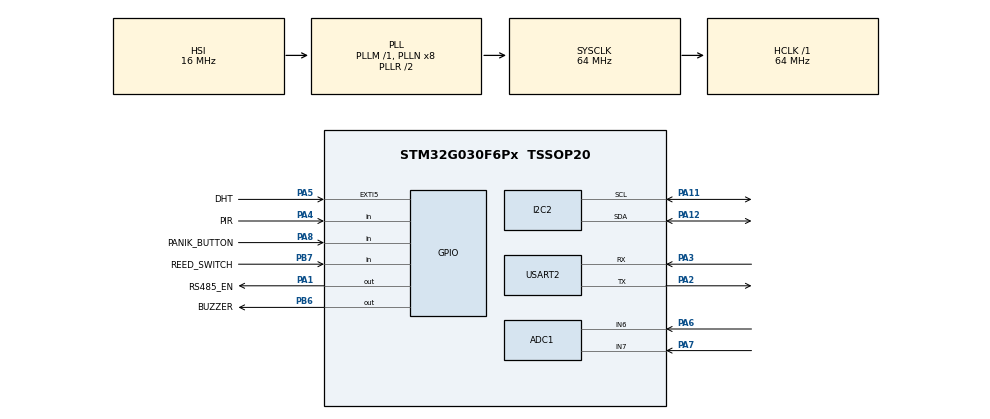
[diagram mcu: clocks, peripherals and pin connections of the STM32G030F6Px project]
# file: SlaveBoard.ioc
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ADC1.Channel-0\#ChannelRegularConversion=ADC_CHANNEL_6
ADC1.Channel-1\#ChannelRegularConversion=ADC_CHANNEL_7
ADC1.NbrOfConversion=2
ADC1.NbrOfConversionFlag=1
ADC1.Rank-0\#ChannelRegularConversion=1
ADC1.Rank-1\#ChannelRegularConversion=2
ADC1.SamplingTime-0\#ChannelRegularConversion=ADC_SAMPLINGTIME_COMMON_1
ADC1.SamplingTime-1\#ChannelRegularConversion=ADC_SAMPLINGTIME_COMMON_1
ADC1.SamplingTimeCommon1=ADC_SAMPLETIME_160CYCLES_5
ADC1.SamplingTimeCommon2=ADC_SAMPLETIME_160CYCLES_5
ADC1.SelectedChannel=ADC_CHANNEL_6|ADC_CHANNEL_7
ADC1.master=1
I2C2.Timing=0x10B17DB5
Mcu.Family=STM32G0
Mcu.Name=STM32G030F6Px
Mcu.Package=TSSOP20
NVIC.EXTI4_15_IRQn=true\:0\:0\:false\:false\:true\:true\:true\:true
NVIC.TIM3_IRQn=true\:0\:0\:false\:false\:true\:true\:true\:true
PA1.GPIO_Label=RS485_EN
PA1.Signal=GPIO_Output
PA11\ [PA9].Mode=I2C
PA11\ [PA9].Signal=I2C2_SCL
PA12\ [PA10].Mode=I2C
PA12\ [PA10].Signal=I2C2_SDA
PA13.Mode=Serial_Wire
PA13.Signal=SYS_SWDIO
PA14-BOOT0.Mode=Serial_Wire
PA14-BOOT0.Signal=SYS_SWCLK
PA14-BOOT0__PA15.StandardMode=true
PA2.Mode=Asynchronous
PA2.Signal=USART2_TX
PA3.Mode=Asynchronous
PA3.Signal=USART2_RX
PA4.GPIO_Label=PIR
PA4.Signal=GPIO_Input
PA5.GPIO_Label=DHT
PA5.Signal=GPXTI5
PA6.Mode=IN6
PA6.Signal=ADC1_IN6
PA7.Mode=IN7
PA7.Signal=ADC1_IN7
PA8.GPIO_Label=PANIK_BUTTON
PA8.Signal=GPIO_Input
PB0__PB1__PB2__PA8.StandardMode=true
PB3__PB4__PB5__PB6.StandardMode=true
PB6.GPIO_Label=BUZZER
PB6.Signal=GPIO_Output
PB7.GPIO_Label=REED_SWITCH
PB7.Signal=GPIO_Input
PB7__PB8.StandardMode=true
PC14-OSC32_IN\ (PC14)__PB9.StandardMode=true
ProjectManager.HeapSize=0x200
ProjectManager.StackSize=0x400
ProjectManager.TargetToolchain=MDK-ARM V5.32
RCC.ADCFreq_Value=64000000
RCC.AHBFreq_Value=64000000
RCC.CortexFreq_Value=64000000
RCC.EXTERNAL_CLOCK_VALUE=12288000
RCC.HCLKFreq_Value=64000000
RCC.HSE_VALUE=8000000
RCC.HSI_VALUE=16000000
RCC.LSE_VALUE=32768
RCC.SYSCLKFreq_VALUE=64000000
RCC.SYSCLKSource=RCC_SYSCLKSOURCE_PLLCLK
RCC.VCOOutputFreq_Value=128000000
TIM3.Prescaler=1000-1
USART2.VirtualMode-Asynchronous=VM_ASYNC
VP_TIM1_VS_ClockSourceINT.Mode=Internal
VP_TIM3_VS_ClockSourceINT.Mode=Internal
board=custom

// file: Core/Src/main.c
/* USER CODE BEGIN Header */
/**
  ******************************************************************************
  * @file           : main.c
  * @brief          : Main program body
  ******************************************************************************
  * @attention
  *
  * Copyright (c) 2025 STMicroelectronics.
  * All rights reserved.
  *
  * This software is licensed under terms that can be found in the LICENSE file
  * in the root directory of this software component.
  * If no LICENSE file comes with this software, it is provided AS-IS.
  *
  ******************************************************************************
  */
/* USER CODE END Header */
#include "main.h"

/* USER CODE BEGIN Includes */
#include "SlaveManager.h"

/* USER CODE END Includes */

ADC_HandleTypeDef hadc1;

I2C_HandleTypeDef hi2c2;

TIM_HandleTypeDef htim1;
TIM_HandleTypeDef htim3;

UART_HandleTypeDef huart2;

void SystemClock_Config(void);
static void MX_GPIO_Init(void);
static void MX_ADC1_Init(void);
static void MX_I2C2_Init(void);
static void MX_TIM1_Init(void);
static void MX_TIM3_Init(void);
static void MX_USART2_UART_Init(void);

int main(void)
{

  /* MCU Configuration--------------------------------------------------------*/

  /* Reset of all peripherals, Initializes the Flash interface and the Systick. */
  HAL_Init();

  /* Configure the system clock */
  SystemClock_Config();

  /* Initialize all configured peripherals */
  MX_GPIO_Init();
  MX_ADC1_Init();
  MX_I2C2_Init();
  MX_TIM1_Init();
  MX_TIM3_Init();
  MX_USART2_UART_Init();
  /* USER CODE BEGIN 2 */
	stSlaveManager_t* slaveManager = SlaveManager_Init(&hadc1, &hi2c2, &huart2, &htim3, &htim1);
  /* USER CODE END 2 */

  /* Infinite loop */
  /* USER CODE BEGIN WHILE */
  while (1)
  {
		SlaveManager_EventLoop( slaveManager );
    /* USER CODE END WHILE */

  }
}

void SystemClock_Config(void)
{
  RCC_OscInitTypeDef RCC_OscInitStruct = {0};
  RCC_ClkInitTypeDef RCC_ClkInitStruct = {0};

  /** Configure the main internal regulator output voltage
  */
  HAL_PWREx_ControlVoltageScaling(PWR_REGULATOR_VOLTAGE_SCALE1);

  /** Initializes the RCC Oscillators according to the specified parameters
  * in the RCC_OscInitTypeDef structure.
  */
  RCC_OscInitStruct.OscillatorType = RCC_OSCILLATORTYPE_HSI;
  RCC_OscInitStruct.HSIState = RCC_HSI_ON;
  RCC_OscInitStruct.HSIDiv = RCC_HSI_DIV1;
  RCC_OscInitStruct.HSICalibrationValue = RCC_HSICALIBRATION_DEFAULT;
  RCC_OscInitStruct.PLL.PLLState = RCC_PLL_ON;
  RCC_OscInitStruct.PLL.PLLSource = RCC_PLLSOURCE_HSI;
  RCC_OscInitStruct.PLL.PLLM = RCC_PLLM_DIV1;
  RCC_OscInitStruct.PLL.PLLN = 8;
  RCC_OscInitStruct.PLL.PLLP = RCC_PLLP_DIV2;
  RCC_OscInitStruct.PLL.PLLR = RCC_PLLR_DIV2;
  if (HAL_RCC_OscConfig(&RCC_OscInitStruct) != HAL_OK)
  {
    Error_Handler();
  }

  /** Initializes the CPU, AHB and APB buses clocks
  */
  RCC_ClkInitStruct.ClockType = RCC_CLOCKTYPE_HCLK|RCC_CLOCKTYPE_SYSCLK
                              |RCC_CLOCKTYPE_PCLK1;
  RCC_ClkInitStruct.SYSCLKSource = RCC_SYSCLKSOURCE_PLLCLK;
  RCC_ClkInitStruct.AHBCLKDivider = RCC_SYSCLK_DIV1;
  RCC_ClkInitStruct.APB1CLKDivider = RCC_HCLK_DIV1;

  if (HAL_RCC_ClockConfig(&RCC_ClkInitStruct, FLASH_LATENCY_2) != HAL_OK)
  {
    Error_Handler();
  }
}

static void MX_ADC1_Init(void)
{

  ADC_ChannelConfTypeDef sConfig = {0};

  /** Configure the global features of the ADC (Clock, Resolution, Data Alignment and number of conversion)
  */
  hadc1.Instance = ADC1;
  hadc1.Init.ClockPrescaler = ADC_CLOCK_SYNC_PCLK_DIV2;
  hadc1.Init.Resolution = ADC_RESOLUTION_12B;
  hadc1.Init.DataAlign = ADC_DATAALIGN_RIGHT;
  hadc1.Init.ScanConvMode = ADC_SCAN_ENABLE;
  hadc1.Init.EOCSelection = ADC_EOC_SINGLE_CONV;
  hadc1.Init.LowPowerAutoWait = DISABLE;
  hadc1.Init.LowPowerAutoPowerOff = DISABLE;
  hadc1.Init.ContinuousConvMode = DISABLE;
  hadc1.Init.NbrOfConversion = 2;
  hadc1.Init.DiscontinuousConvMode = DISABLE;
  hadc1.Init.ExternalTrigConv = ADC_SOFTWARE_START;
  hadc1.Init.ExternalTrigConvEdge = ADC_EXTERNALTRIGCONVEDGE_NONE;
  hadc1.Init.DMAContinuousRequests = DISABLE;
  hadc1.Init.Overrun = ADC_OVR_DATA_PRESERVED;
  hadc1.Init.SamplingTimeCommon1 = ADC_SAMPLETIME_160CYCLES_5;
  hadc1.Init.SamplingTimeCommon2 = ADC_SAMPLETIME_160CYCLES_5;
  hadc1.Init.OversamplingMode = DISABLE;
  hadc1.Init.TriggerFrequencyMode = ADC_TRIGGER_FREQ_HIGH;
  if (HAL_ADC_Init(&hadc1) != HAL_OK)
  {
    Error_Handler();
  }

  /** Configure Regular Channel
  */
  sConfig.Channel = ADC_CHANNEL_6;
  sConfig.Rank = ADC_REGULAR_RANK_1;
  sConfig.SamplingTime = ADC_SAMPLINGTIME_COMMON_1;
  if (HAL_ADC_ConfigChannel(&hadc1, &sConfig) != HAL_OK)
  {
    Error_Handler();
  }

  /** Configure Regular Channel
  */
  sConfig.Channel = ADC_CHANNEL_7;
  sConfig.Rank = ADC_REGULAR_RANK_2;
  if (HAL_ADC_ConfigChannel(&hadc1, &sConfig) != HAL_OK)
  {
    Error_Handler();
  }

}

static void MX_I2C2_Init(void)
{

  hi2c2.Instance = I2C2;
  hi2c2.Init.Timing = 0x10B17DB5;
  hi2c2.Init.OwnAddress1 = 0;
  hi2c2.Init.AddressingMode = I2C_ADDRESSINGMODE_7BIT;
  hi2c2.Init.DualAddressMode = I2C_DUALADDRESS_DISABLE;
  hi2c2.Init.OwnAddress2 = 0;
  hi2c2.Init.OwnAddress2Masks = I2C_OA2_NOMASK;
  hi2c2.Init.GeneralCallMode = I2C_GENERALCALL_DISABLE;
  hi2c2.Init.NoStretchMode = I2C_NOSTRETCH_DISABLE;
  if (HAL_I2C_Init(&hi2c2) != HAL_OK)
  {
    Error_Handler();
  }

  /** Configure Analogue filter
  */
  if (HAL_I2CEx_ConfigAnalogFilter(&hi2c2, I2C_ANALOGFILTER_ENABLE) != HAL_OK)
  {
    Error_Handler();
  }

  /** Configure Digital filter
  */
  if (HAL_I2CEx_ConfigDigitalFilter(&hi2c2, 0) != HAL_OK)
  {
    Error_Handler();
  }

}

static void MX_TIM1_Init(void)
{

  TIM_ClockConfigTypeDef sClockSourceConfig = {0};
  TIM_MasterConfigTypeDef sMasterConfig = {0};

  htim1.Instance = TIM1;
  htim1.Init.Prescaler = 0;
  htim1.Init.CounterMode = TIM_COUNTERMODE_UP;
  htim1.Init.Period = 65535;
  htim1.Init.ClockDivision = TIM_CLOCKDIVISION_DIV1;
  htim1.Init.RepetitionCounter = 0;
  htim1.Init.AutoReloadPreload = TIM_AUTORELOAD_PRELOAD_DISABLE;
  if (HAL_TIM_Base_Init(&htim1) != HAL_OK)
  {
    Error_Handler();
  }
  sClockSourceConfig.ClockSource = TIM_CLOCKSOURCE_INTERNAL;
  if (HAL_TIM_ConfigClockSource(&htim1, &sClockSourceConfig) != HAL_OK)
  {
    Error_Handler();
  }
  sMasterConfig.MasterOutputTrigger = TIM_TRGO_RESET;
  sMasterConfig.MasterOutputTrigger2 = TIM_TRGO2_RESET;
  sMasterConfig.MasterSlaveMode = TIM_MASTERSLAVEMODE_DISABLE;
  if (HAL_TIMEx_MasterConfigSynchronization(&htim1, &sMasterConfig) != HAL_OK)
  {
    Error_Handler();
  }

}

static void MX_TIM3_Init(void)
{

  TIM_ClockConfigTypeDef sClockSourceConfig = {0};
  TIM_MasterConfigTypeDef sMasterConfig = {0};

  htim3.Instance = TIM3;
  htim3.Init.Prescaler = 1000-1;
  htim3.Init.CounterMode = TIM_COUNTERMODE_UP;
  htim3.Init.Period = 65535;
  htim3.Init.ClockDivision = TIM_CLOCKDIVISION_DIV1;
  htim3.Init.AutoReloadPreload = TIM_AUTORELOAD_PRELOAD_DISABLE;
  if (HAL_TIM_Base_Init(&htim3) != HAL_OK)
  {
    Error_Handler();
  }
  sClockSourceConfig.ClockSource = TIM_CLOCKSOURCE_INTERNAL;
  if (HAL_TIM_ConfigClockSource(&htim3, &sClockSourceConfig) != HAL_OK)
  {
    Error_Handler();
  }
  sMasterConfig.MasterOutputTrigger = TIM_TRGO_RESET;
  sMasterConfig.MasterSlaveMode = TIM_MASTERSLAVEMODE_DISABLE;
  if (HAL_TIMEx_MasterConfigSynchronization(&htim3, &sMasterConfig) != HAL_OK)
  {
    Error_Handler();
  }

}

static void MX_USART2_UART_Init(void)
{

  huart2.Instance = USART2;
  huart2.Init.BaudRate = 115200;
  huart2.Init.WordLength = UART_WORDLENGTH_8B;
  huart2.Init.StopBits = UART_STOPBITS_1;
  huart2.Init.Parity = UART_PARITY_NONE;
  huart2.Init.Mode = UART_MODE_TX_RX;
  huart2.Init.HwFlowCtl = UART_HWCONTROL_NONE;
  huart2.Init.OverSampling = UART_OVERSAMPLING_16;
  huart2.Init.OneBitSampling = UART_ONE_BIT_SAMPLE_DISABLE;
  huart2.Init.ClockPrescaler = UART_PRESCALER_DIV1;
  huart2.AdvancedInit.AdvFeatureInit = UART_ADVFEATURE_NO_INIT;
  if (HAL_UART_Init(&huart2) != HAL_OK)
  {
    Error_Handler();
  }

}

static void MX_GPIO_Init(void)
{
  GPIO_InitTypeDef GPIO_InitStruct = {0};

  /* GPIO Ports Clock Enable */
  __HAL_RCC_GPIOB_CLK_ENABLE();
  __HAL_RCC_GPIOA_CLK_ENABLE();

  /*Configure GPIO pin Output Level */
  HAL_GPIO_WritePin(RS485_EN_GPIO_Port, RS485_EN_Pin, GPIO_PIN_RESET);

  /*Configure GPIO pin Output Level */
  HAL_GPIO_WritePin(BUZZER_GPIO_Port, BUZZER_Pin, GPIO_PIN_RESET);

  /*Configure GPIO pin : REED_SWITCH_Pin */
  GPIO_InitStruct.Pin = REED_SWITCH_Pin;
  GPIO_InitStruct.Mode = GPIO_MODE_INPUT;
  GPIO_InitStruct.Pull = GPIO_NOPULL;
  HAL_GPIO_Init(REED_SWITCH_GPIO_Port, &GPIO_InitStruct);

  /*Configure GPIO pin : RS485_EN_Pin */
  GPIO_InitStruct.Pin = RS485_EN_Pin;
  GPIO_InitStruct.Mode = GPIO_MODE_OUTPUT_PP;
  GPIO_InitStruct.Pull = GPIO_NOPULL;
  GPIO_InitStruct.Speed = GPIO_SPEED_FREQ_LOW;
  HAL_GPIO_Init(RS485_EN_GPIO_Port, &GPIO_InitStruct);

  /*Configure GPIO pins : PIR_Pin PANIK_BUTTON_Pin */
  GPIO_InitStruct.Pin = PIR_Pin|PANIK_BUTTON_Pin;
  GPIO_InitStruct.Mode = GPIO_MODE_INPUT;
  GPIO_InitStruct.Pull = GPIO_NOPULL;
  HAL_GPIO_Init(GPIOA, &GPIO_InitStruct);

  /*Configure GPIO pin : DHT_Pin */
  GPIO_InitStruct.Pin = DHT_Pin;
  GPIO_InitStruct.Mode = GPIO_MODE_IT_RISING;
  GPIO_InitStruct.Pull = GPIO_NOPULL;
  HAL_GPIO_Init(DHT_GPIO_Port, &GPIO_InitStruct);

  /*Configure GPIO pin : BUZZER_Pin */
  GPIO_InitStruct.Pin = BUZZER_Pin;
  GPIO_InitStruct.Mode = GPIO_MODE_OUTPUT_PP;
  GPIO_InitStruct.Pull = GPIO_NOPULL;
  GPIO_InitStruct.Speed = GPIO_SPEED_FREQ_LOW;
  HAL_GPIO_Init(BUZZER_GPIO_Port, &GPIO_InitStruct);

  /* EXTI interrupt init*/
  HAL_NVIC_SetPriority(EXTI4_15_IRQn, 0, 0);
  HAL_NVIC_EnableIRQ(EXTI4_15_IRQn);

}

void Error_Handler(void)
{
  __disable_irq();
  while (1)
  {
  }
}
